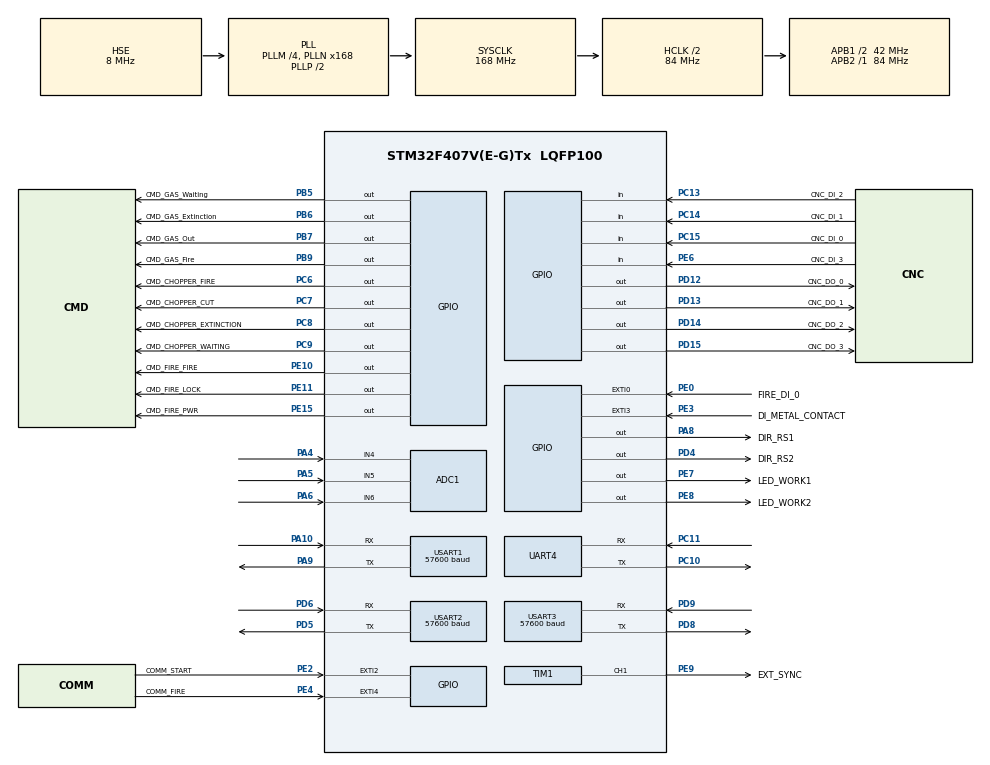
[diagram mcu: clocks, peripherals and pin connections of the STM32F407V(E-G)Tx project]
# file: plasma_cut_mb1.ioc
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ADC1.Channel-0\#ChannelRegularConversion=ADC_CHANNEL_4
ADC1.Channel-1\#ChannelRegularConversion=ADC_CHANNEL_5
ADC1.Channel-2\#ChannelRegularConversion=ADC_CHANNEL_6
ADC1.ContinuousConvMode=ENABLE
ADC1.DMAContinuousRequests=ENABLE
ADC1.DiscontinuousConvMode=DISABLE
ADC1.EOCSelection=ADC_EOC_SEQ_CONV
ADC1.InjNumberOfConversion=0
ADC1.NbrOfConversion=3
ADC1.NbrOfConversionFlag=1
ADC1.Rank-0\#ChannelRegularConversion=1
ADC1.Rank-1\#ChannelRegularConversion=2
ADC1.Rank-2\#ChannelRegularConversion=3
ADC1.SamplingTime-0\#ChannelRegularConversion=ADC_SAMPLETIME_112CYCLES
ADC1.SamplingTime-1\#ChannelRegularConversion=ADC_SAMPLETIME_112CYCLES
ADC1.SamplingTime-2\#ChannelRegularConversion=ADC_SAMPLETIME_112CYCLES
ADC1.master=1
Dma.ADC1.4.Direction=DMA_PERIPH_TO_MEMORY
Dma.ADC1.4.FIFOMode=DMA_FIFOMODE_DISABLE
Dma.ADC1.4.Instance=DMA2_Stream0
Dma.ADC1.4.MemDataAlignment=DMA_MDATAALIGN_HALFWORD
Dma.ADC1.4.MemInc=DMA_MINC_ENABLE
Dma.ADC1.4.Mode=DMA_CIRCULAR
Dma.ADC1.4.PeriphDataAlignment=DMA_PDATAALIGN_HALFWORD
Dma.ADC1.4.PeriphInc=DMA_PINC_DISABLE
Dma.ADC1.4.Priority=DMA_PRIORITY_LOW
Dma.Request0=USART1_TX
Dma.Request1=USART2_TX
Dma.Request2=USART3_TX
Dma.Request3=UART4_TX
Dma.Request4=ADC1
Dma.UART4_TX.3.Direction=DMA_MEMORY_TO_PERIPH
Dma.UART4_TX.3.FIFOMode=DMA_FIFOMODE_DISABLE
Dma.UART4_TX.3.Instance=DMA1_Stream4
Dma.UART4_TX.3.MemDataAlignment=DMA_MDATAALIGN_BYTE
Dma.UART4_TX.3.MemInc=DMA_MINC_ENABLE
Dma.UART4_TX.3.Mode=DMA_NORMAL
Dma.UART4_TX.3.PeriphDataAlignment=DMA_PDATAALIGN_BYTE
Dma.UART4_TX.3.PeriphInc=DMA_PINC_DISABLE
Dma.UART4_TX.3.Priority=DMA_PRIORITY_LOW
Dma.USART1_TX.0.Direction=DMA_MEMORY_TO_PERIPH
Dma.USART1_TX.0.FIFOMode=DMA_FIFOMODE_DISABLE
Dma.USART1_TX.0.Instance=DMA2_Stream7
Dma.USART1_TX.0.MemDataAlignment=DMA_MDATAALIGN_BYTE
Dma.USART1_TX.0.MemInc=DMA_MINC_ENABLE
Dma.USART1_TX.0.Mode=DMA_NORMAL
Dma.USART1_TX.0.PeriphDataAlignment=DMA_PDATAALIGN_BYTE
Dma.USART1_TX.0.PeriphInc=DMA_PINC_DISABLE
Dma.USART1_TX.0.Priority=DMA_PRIORITY_LOW
Dma.USART2_TX.1.Direction=DMA_MEMORY_TO_PERIPH
Dma.USART2_TX.1.FIFOMode=DMA_FIFOMODE_DISABLE
Dma.USART2_TX.1.Instance=DMA1_Stream6
Dma.USART2_TX.1.MemDataAlignment=DMA_MDATAALIGN_BYTE
Dma.USART2_TX.1.MemInc=DMA_MINC_ENABLE
Dma.USART2_TX.1.Mode=DMA_NORMAL
Dma.USART2_TX.1.PeriphDataAlignment=DMA_PDATAALIGN_BYTE
Dma.USART2_TX.1.PeriphInc=DMA_PINC_DISABLE
Dma.USART2_TX.1.Priority=DMA_PRIORITY_LOW
Dma.USART3_TX.2.Direction=DMA_MEMORY_TO_PERIPH
Dma.USART3_TX.2.FIFOMode=DMA_FIFOMODE_DISABLE
Dma.USART3_TX.2.Instance=DMA1_Stream3
Dma.USART3_TX.2.MemDataAlignment=DMA_MDATAALIGN_BYTE
Dma.USART3_TX.2.MemInc=DMA_MINC_ENABLE
Dma.USART3_TX.2.Mode=DMA_NORMAL
Dma.USART3_TX.2.PeriphDataAlignment=DMA_PDATAALIGN_BYTE
Dma.USART3_TX.2.PeriphInc=DMA_PINC_DISABLE
Dma.USART3_TX.2.Priority=DMA_PRIORITY_LOW
Mcu.Family=STM32F4
Mcu.Name=STM32F407V(E-G)Tx
Mcu.Package=LQFP100
NVIC.DMA1_Stream3_IRQn=true\:0\:0\:false\:false\:true\:false\:true\:true
NVIC.DMA1_Stream4_IRQn=true\:0\:0\:false\:false\:true\:false\:true\:true
NVIC.DMA1_Stream6_IRQn=true\:0\:0\:false\:false\:true\:false\:true\:true
NVIC.DMA2_Stream0_IRQn=true\:0\:0\:false\:false\:true\:false\:true\:true
NVIC.DMA2_Stream7_IRQn=true\:0\:0\:false\:false\:true\:false\:true\:true
NVIC.EXTI0_IRQn=true\:0\:0\:false\:false\:true\:true\:true\:true
NVIC.EXTI2_IRQn=true\:0\:0\:false\:false\:true\:true\:true\:true
NVIC.EXTI3_IRQn=true\:0\:0\:false\:false\:true\:true\:true\:true
NVIC.EXTI4_IRQn=true\:0\:0\:false\:false\:true\:true\:true\:true
NVIC.PriorityGroup=NVIC_PRIORITYGROUP_4
NVIC.TIM3_IRQn=true\:0\:0\:false\:false\:true\:true\:true\:true
NVIC.TIM4_IRQn=true\:0\:0\:false\:false\:true\:true\:true\:true
NVIC.UART4_IRQn=true\:0\:0\:false\:false\:true\:true\:true\:true
NVIC.USART1_IRQn=true\:0\:0\:false\:false\:true\:true\:true\:true
NVIC.USART2_IRQn=true\:0\:0\:false\:false\:true\:true\:true\:true
NVIC.USART3_IRQn=true\:0\:0\:false\:false\:true\:true\:true\:true
PA10.Mode=Asynchronous
PA10.Signal=USART1_RX
PA13.Mode=Serial_Wire
PA13.Signal=SYS_JTMS-SWDIO
PA14.Mode=Serial_Wire
PA14.Signal=SYS_JTCK-SWCLK
PA4.Signal=ADCx_IN4
PA5.Signal=ADCx_IN5
PA6.Signal=ADCx_IN6
PA8.GPIO_Label=DIR_RS1
PA8.Signal=GPIO_Output
PA9.Mode=Asynchronous
PA9.Signal=USART1_TX
PB5.GPIO_Label=CMD_GAS_Waiting
PB5.GPIO_ModeDefaultOutputPP=GPIO_MODE_OUTPUT_PP
PB5.GPIO_PuPd=GPIO_PULLDOWN
PB5.GPIO_Speed=GPIO_SPEED_FREQ_MEDIUM
PB5.PinState=GPIO_PIN_RESET
PB5.Signal=GPIO_Output
PB6.GPIO_Label=CMD_GAS_Extinction
PB6.GPIO_ModeDefaultOutputPP=GPIO_MODE_OUTPUT_PP
PB6.GPIO_PuPd=GPIO_PULLDOWN
PB6.GPIO_Speed=GPIO_SPEED_FREQ_MEDIUM
PB6.PinState=GPIO_PIN_RESET
PB6.Signal=GPIO_Output
PB7.GPIO_Label=CMD_GAS_Out
PB7.GPIO_ModeDefaultOutputPP=GPIO_MODE_OUTPUT_PP
PB7.GPIO_PuPd=GPIO_PULLDOWN
PB7.GPIO_Speed=GPIO_SPEED_FREQ_MEDIUM
PB7.PinState=GPIO_PIN_RESET
PB7.Signal=GPIO_Output
PB8.Signal=S_TIM10_CH1
PB9.GPIO_Label=CMD_GAS_Fire
PB9.GPIO_ModeDefaultOutputPP=GPIO_MODE_OUTPUT_PP
PB9.GPIO_PuPd=GPIO_PULLDOWN
PB9.GPIO_Speed=GPIO_SPEED_FREQ_MEDIUM
PB9.PinState=GPIO_PIN_RESET
PB9.Signal=GPIO_Output
PC10.Mode=Asynchronous
PC10.Signal=UART4_TX
PC11.Mode=Asynchronous
PC11.Signal=UART4_RX
PC13-ANTI_TAMP.GPIO_Label=CNC_DI_2
PC13-ANTI_TAMP.Signal=GPIO_Input
PC14-OSC32_IN.GPIO_Label=CNC_DI_1
PC14-OSC32_IN.Signal=GPIO_Input
PC15-OSC32_OUT.GPIO_Label=CNC_DI_0
PC15-OSC32_OUT.Signal=GPIO_Input
PC6.GPIO_Label=CMD_CHOPPER_FIRE
PC6.Signal=GPIO_Output
PC7.GPIO_Label=CMD_CHOPPER_CUT
PC7.Signal=GPIO_Output
PC8.GPIO_Label=CMD_CHOPPER_EXTINCTION
PC8.Signal=GPIO_Output
PC9.GPIO_Label=CMD_CHOPPER_WAITING
PC9.Signal=GPIO_Output
PD0.Signal=CAN1_RX
PD12.GPIO_Label=CNC_DO_0
PD12.GPIO_ModeDefaultOutputPP=GPIO_MODE_OUTPUT_PP
PD12.GPIO_PuPd=GPIO_PULLDOWN
PD12.GPIO_Speed=GPIO_SPEED_FREQ_LOW
PD12.PinState=GPIO_PIN_RESET
PD12.Signal=GPIO_Output
PD13.GPIO_Label=CNC_DO_1
PD13.GPIO_ModeDefaultOutputPP=GPIO_MODE_OUTPUT_PP
PD13.GPIO_PuPd=GPIO_PULLDOWN
PD13.GPIO_Speed=GPIO_SPEED_FREQ_LOW
PD13.PinState=GPIO_PIN_RESET
PD13.Signal=GPIO_Output
PD14.GPIO_Label=CNC_DO_2
PD14.GPIO_ModeDefaultOutputPP=GPIO_MODE_OUTPUT_PP
PD14.GPIO_PuPd=GPIO_PULLDOWN
PD14.GPIO_Speed=GPIO_SPEED_FREQ_LOW
PD14.PinState=GPIO_PIN_RESET
PD14.Signal=GPIO_Output
PD15.GPIO_Label=CNC_DO_3
PD15.GPIO_ModeDefaultOutputPP=GPIO_MODE_OUTPUT_PP
PD15.GPIO_PuPd=GPIO_PULLDOWN
PD15.GPIO_Speed=GPIO_SPEED_FREQ_LOW
PD15.PinState=GPIO_PIN_RESET
PD15.Signal=GPIO_Output
PD4.GPIO_Label=DIR_RS2
PD4.Signal=GPIO_Output
PD5.Mode=Asynchronous
PD5.Signal=USART2_TX
PD6.Mode=Asynchronous
PD6.Signal=USART2_RX
PD8.Mode=Asynchronous
PD8.Signal=USART3_TX
PD9.Mode=Asynchronous
PD9.Signal=USART3_RX
PE0.GPIO_Label=FIRE_DI_0
PE0.Signal=GPXTI0
PE10.GPIO_Label=CMD_FIRE_FIRE
PE10.Signal=GPIO_Output
PE11.GPIO_Label=CMD_FIRE_LOCK
PE11.Signal=GPIO_Output
PE15.GPIO_Label=CMD_FIRE_PWR
PE15.Signal=GPIO_Output
PE2.GPIO_Label=COMM_START
PE2.GPIO_ModeDefaultEXTI=GPIO_MODE_IT_FALLING
PE2.Signal=GPXTI2
PE3.GPIO_Label=DI_METAL_CONTACT
PE3.GPIO_ModeDefaultEXTI=GPIO_MODE_IT_FALLING
PE3.Signal=GPXTI3
PE4.GPIO_Label=COMM_FIRE
PE4.GPIO_ModeDefaultEXTI=GPIO_MODE_IT_FALLING
PE4.Signal=GPXTI4
PE6.GPIO_Label=CNC_DI_3
PE6.Signal=GPIO_Input
PE7.GPIO_Label=LED_WORK1
PE7.Signal=GPIO_Output
PE8.GPIO_Label=LED_WORK2
PE8.Signal=GPIO_Output
PE9.GPIO_Label=EXT_SYNC
PE9.Signal=S_TIM1_CH1
PH0-OSC_IN.Mode=HSE-External-Oscillator
PH0-OSC_IN.Signal=RCC_OSC_IN
PH1-OSC_OUT.Mode=HSE-External-Oscillator
PH1-OSC_OUT.Signal=RCC_OSC_OUT
ProjectManager.HeapSize=0x1200
ProjectManager.StackSize=0x2000
ProjectManager.TargetToolchain=EWARM V8.32
RCC.48MHZClocksFreq_Value=84000000
RCC.AHBCLKDivider=RCC_SYSCLK_DIV2
RCC.AHBFreq_Value=84000000
RCC.APB1CLKDivider=RCC_HCLK_DIV2
RCC.APB1Freq_Value=42000000
RCC.APB1TimFreq_Value=84000000
RCC.APB2Freq_Value=84000000
RCC.APB2TimFreq_Value=84000000
RCC.CortexFreq_Value=84000000
RCC.HCLKFreq_Value=84000000
RCC.HSE_VALUE=8000000
RCC.HSI_VALUE=16000000
RCC.LSE_VALUE=32768
RCC.PLLM=4
RCC.PLLN=168
RCC.PLLSourceVirtual=RCC_PLLSOURCE_HSE
RCC.SYSCLKFreq_VALUE=168000000
RCC.SYSCLKSource=RCC_SYSCLKSOURCE_PLLCLK
RCC.VCOOutputFreq_Value=336000000
SH.ADCx_IN4.0=ADC1_IN4,IN4
SH.ADCx_IN5.0=ADC1_IN5,IN5
SH.ADCx_IN6.0=ADC1_IN6,IN6
SH.S_TIM10_CH1.0=TIM10_CH1
SH.S_TIM1_CH1.0=TIM1_CH1,PWM Generation1 CH1
TIM1.AutoReloadPreload=TIM_AUTORELOAD_PRELOAD_ENABLE
TIM1.Channel-PWM\ Generation1\ CH1=TIM_CHANNEL_1
TIM1.Period=7000
TIM1.Pulse-PWM\ Generation1\ CH1=3500
TIM3.AutoReloadPreload=TIM_AUTORELOAD_PRELOAD_ENABLE
TIM3.TIM_MasterOutputTrigger=TIM_TRGO_UPDATE
TIM4.AutoReloadPreload=TIM_AUTORELOAD_PRELOAD_ENABLE
TIM4.TIM_MasterOutputTrigger=TIM_TRGO_UPDATE
UART4.VirtualMode=Asynchronous
USART1.BaudRate=57600
USART1.VirtualMode=VM_ASYNC
USART2.BaudRate=57600
USART2.VirtualMode=VM_ASYNC
USART3.BaudRate=57600
USART3.VirtualMode=VM_ASYNC
VP_TIM1_VS_ClockSourceINT.Mode=Internal
VP_TIM3_VS_ClockSourceINT.Mode=Internal
VP_TIM4_VS_ClockSourceINT.Mode=Internal
board=custom

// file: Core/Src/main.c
/* USER CODE BEGIN Header */
/**
  ******************************************************************************
  * @file           : main.c
  * @brief          : Main program body
  ******************************************************************************
  * @attention
  *
  * Copyright (c) 2023 STMicroelectronics.
  * All rights reserved.
  *
  * This software is licensed under terms that can be found in the LICENSE file
  * in the root directory of this software component.
  * If no LICENSE file comes with this software, it is provided AS-IS.
  *
  ******************************************************************************
  */
/* USER CODE END Header */
#include "main.h"

/* USER CODE BEGIN Includes */
#include "StateMachine.h"
/* USER CODE END Includes */

ADC_HandleTypeDef hadc1;
DMA_HandleTypeDef hdma_adc1;

TIM_HandleTypeDef htim1;
TIM_HandleTypeDef htim3;
TIM_HandleTypeDef htim4;

UART_HandleTypeDef huart4;
UART_HandleTypeDef huart1;
UART_HandleTypeDef huart2;
UART_HandleTypeDef huart3;
DMA_HandleTypeDef hdma_uart4_tx;
DMA_HandleTypeDef hdma_usart1_tx;
DMA_HandleTypeDef hdma_usart2_tx;
DMA_HandleTypeDef hdma_usart3_tx;

/* USER CODE BEGIN PV */

UART_HandleTypeDef* pMBSlave     = &huart1; // RS485_1_slave(to PC)
UART_HandleTypeDef* pMBMaster    = &huart2; // RS485_2_master(to Cells)

UART_HandleTypeDef* pUartWIFI    = &huart4; // WIFI
UART_HandleTypeDef* pUartDBG     = &huart3; // UART_DEBUG

TIM_HandleTypeDef* pMBTimMaster = &htim3; //
TIM_HandleTypeDef* pMBTimSlave  = &htim4; //
TIM_HandleTypeDef* pExtSync     = &htim1; //

/* USER CODE END PV */

void SystemClock_Config(void);
static void MX_GPIO_Init(void);
static void MX_DMA_Init(void);
static void MX_USART3_UART_Init(void);
static void MX_UART4_Init(void);
static void MX_USART1_UART_Init(void);
static void MX_USART2_UART_Init(void);
static void MX_ADC1_Init(void);
static void MX_TIM3_Init(void);
static void MX_TIM4_Init(void);
static void MX_TIM1_Init(void);

int main(void)
{

  /* MCU Configuration--------------------------------------------------------*/

  /* Reset of all peripherals, Initializes the Flash interface and the Systick. */
  HAL_Init();

  /* Configure the system clock */
  SystemClock_Config();

  /* Initialize all configured peripherals */
  MX_GPIO_Init();
  MX_DMA_Init();
  MX_USART3_UART_Init();
  MX_UART4_Init();
  MX_USART1_UART_Init();
  MX_USART2_UART_Init();
  MX_ADC1_Init();
  MX_TIM3_Init();
  MX_TIM4_Init();
  MX_TIM1_Init();
  /* USER CODE BEGIN 2 */
  ProcessInit();
  if ( HAL_OK != HAL_ADC_Start_DMA( &hadc1, (uint32_t*)ADCdata,  eChanMax*ADC_BUF_LENGHT ))
  {
    Error_Handler();
  }
  /* USER CODE END 2 */

  /* Infinite loop */
  /* USER CODE BEGIN WHILE */
  while ( 1 )
  {
    SM_loop( );
    /* USER CODE END WHILE */

  }
}

void SystemClock_Config(void)
{
  RCC_OscInitTypeDef RCC_OscInitStruct = {0};
  RCC_ClkInitTypeDef RCC_ClkInitStruct = {0};

  /** Configure the main internal regulator output voltage
  */
  __HAL_RCC_PWR_CLK_ENABLE();
  __HAL_PWR_VOLTAGESCALING_CONFIG(PWR_REGULATOR_VOLTAGE_SCALE1);

  /** Initializes the RCC Oscillators according to the specified parameters
  * in the RCC_OscInitTypeDef structure.
  */
  RCC_OscInitStruct.OscillatorType = RCC_OSCILLATORTYPE_HSE;
  RCC_OscInitStruct.HSEState = RCC_HSE_ON;
  RCC_OscInitStruct.PLL.PLLState = RCC_PLL_ON;
  RCC_OscInitStruct.PLL.PLLSource = RCC_PLLSOURCE_HSE;
  RCC_OscInitStruct.PLL.PLLM = 4;
  RCC_OscInitStruct.PLL.PLLN = 168;
  RCC_OscInitStruct.PLL.PLLP = RCC_PLLP_DIV2;
  RCC_OscInitStruct.PLL.PLLQ = 4;
  if (HAL_RCC_OscConfig(&RCC_OscInitStruct) != HAL_OK)
  {
    Error_Handler();
  }

  /** Initializes the CPU, AHB and APB buses clocks
  */
  RCC_ClkInitStruct.ClockType = RCC_CLOCKTYPE_HCLK|RCC_CLOCKTYPE_SYSCLK
                              |RCC_CLOCKTYPE_PCLK1|RCC_CLOCKTYPE_PCLK2;
  RCC_ClkInitStruct.SYSCLKSource = RCC_SYSCLKSOURCE_PLLCLK;
  RCC_ClkInitStruct.AHBCLKDivider = RCC_SYSCLK_DIV2;
  RCC_ClkInitStruct.APB1CLKDivider = RCC_HCLK_DIV2;
  RCC_ClkInitStruct.APB2CLKDivider = RCC_HCLK_DIV1;

  if (HAL_RCC_ClockConfig(&RCC_ClkInitStruct, FLASH_LATENCY_2) != HAL_OK)
  {
    Error_Handler();
  }
}

static void MX_ADC1_Init(void)
{

  ADC_ChannelConfTypeDef sConfig = {0};

  /** Configure the global features of the ADC (Clock, Resolution, Data Alignment and number of conversion)
  */
  hadc1.Instance = ADC1;
  hadc1.Init.ClockPrescaler = ADC_CLOCK_SYNC_PCLK_DIV4;
  hadc1.Init.Resolution = ADC_RESOLUTION_12B;
  hadc1.Init.ScanConvMode = ENABLE;
  hadc1.Init.ContinuousConvMode = ENABLE;
  hadc1.Init.DiscontinuousConvMode = DISABLE;
  hadc1.Init.ExternalTrigConvEdge = ADC_EXTERNALTRIGCONVEDGE_NONE;
  hadc1.Init.ExternalTrigConv = ADC_SOFTWARE_START;
  hadc1.Init.DataAlign = ADC_DATAALIGN_RIGHT;
  hadc1.Init.NbrOfConversion = 3;
  hadc1.Init.DMAContinuousRequests = ENABLE;
  hadc1.Init.EOCSelection = ADC_EOC_SEQ_CONV;
  if (HAL_ADC_Init(&hadc1) != HAL_OK)
  {
    Error_Handler();
  }

  /** Configure for the selected ADC regular channel its corresponding rank in the sequencer and its sample time.
  */
  sConfig.Channel = ADC_CHANNEL_4;
  sConfig.Rank = 1;
  sConfig.SamplingTime = ADC_SAMPLETIME_112CYCLES;
  if (HAL_ADC_ConfigChannel(&hadc1, &sConfig) != HAL_OK)
  {
    Error_Handler();
  }

  /** Configure for the selected ADC regular channel its corresponding rank in the sequencer and its sample time.
  */
  sConfig.Channel = ADC_CHANNEL_5;
  sConfig.Rank = 2;
  if (HAL_ADC_ConfigChannel(&hadc1, &sConfig) != HAL_OK)
  {
    Error_Handler();
  }

  /** Configure for the selected ADC regular channel its corresponding rank in the sequencer and its sample time.
  */
  sConfig.Channel = ADC_CHANNEL_6;
  sConfig.Rank = 3;
  if (HAL_ADC_ConfigChannel(&hadc1, &sConfig) != HAL_OK)
  {
    Error_Handler();
  }
  /* USER CODE BEGIN ADC1_Init 2 */
  sConfig.Channel = ADC_CHANNEL_4;
  /* USER CODE END ADC1_Init 2 */

}

static void MX_TIM1_Init(void)
{

  TIM_ClockConfigTypeDef sClockSourceConfig = {0};
  TIM_MasterConfigTypeDef sMasterConfig = {0};
  TIM_OC_InitTypeDef sConfigOC = {0};
  TIM_BreakDeadTimeConfigTypeDef sBreakDeadTimeConfig = {0};

  htim1.Instance = TIM1;
  htim1.Init.Prescaler = 0;
  htim1.Init.CounterMode = TIM_COUNTERMODE_UP;
  htim1.Init.Period = 7000;
  htim1.Init.ClockDivision = TIM_CLOCKDIVISION_DIV1;
  htim1.Init.RepetitionCounter = 0;
  htim1.Init.AutoReloadPreload = TIM_AUTORELOAD_PRELOAD_ENABLE;
  if (HAL_TIM_Base_Init(&htim1) != HAL_OK)
  {
    Error_Handler();
  }
  sClockSourceConfig.ClockSource = TIM_CLOCKSOURCE_INTERNAL;
  if (HAL_TIM_ConfigClockSource(&htim1, &sClockSourceConfig) != HAL_OK)
  {
    Error_Handler();
  }
  if (HAL_TIM_PWM_Init(&htim1) != HAL_OK)
  {
    Error_Handler();
  }
  sMasterConfig.MasterOutputTrigger = TIM_TRGO_RESET;
  sMasterConfig.MasterSlaveMode = TIM_MASTERSLAVEMODE_DISABLE;
  if (HAL_TIMEx_MasterConfigSynchronization(&htim1, &sMasterConfig) != HAL_OK)
  {
    Error_Handler();
  }
  sConfigOC.OCMode = TIM_OCMODE_PWM1;
  sConfigOC.Pulse = 3500;
  sConfigOC.OCPolarity = TIM_OCPOLARITY_HIGH;
  sConfigOC.OCNPolarity = TIM_OCNPOLARITY_HIGH;
  sConfigOC.OCFastMode = TIM_OCFAST_DISABLE;
  sConfigOC.OCIdleState = TIM_OCIDLESTATE_RESET;
  sConfigOC.OCNIdleState = TIM_OCNIDLESTATE_RESET;
  if (HAL_TIM_PWM_ConfigChannel(&htim1, &sConfigOC, TIM_CHANNEL_1) != HAL_OK)
  {
    Error_Handler();
  }
  sBreakDeadTimeConfig.OffStateRunMode = TIM_OSSR_DISABLE;
  sBreakDeadTimeConfig.OffStateIDLEMode = TIM_OSSI_DISABLE;
  sBreakDeadTimeConfig.LockLevel = TIM_LOCKLEVEL_OFF;
  sBreakDeadTimeConfig.DeadTime = 0;
  sBreakDeadTimeConfig.BreakState = TIM_BREAK_DISABLE;
  sBreakDeadTimeConfig.BreakPolarity = TIM_BREAKPOLARITY_HIGH;
  sBreakDeadTimeConfig.AutomaticOutput = TIM_AUTOMATICOUTPUT_DISABLE;
  if (HAL_TIMEx_ConfigBreakDeadTime(&htim1, &sBreakDeadTimeConfig) != HAL_OK)
  {
    Error_Handler();
  }
  HAL_TIM_MspPostInit(&htim1);

}

static void MX_TIM3_Init(void)
{

  TIM_ClockConfigTypeDef sClockSourceConfig = {0};
  TIM_MasterConfigTypeDef sMasterConfig = {0};

  htim3.Instance = TIM3;
  htim3.Init.Prescaler = 0;
  htim3.Init.CounterMode = TIM_COUNTERMODE_UP;
  htim3.Init.Period = 65535;
  htim3.Init.ClockDivision = TIM_CLOCKDIVISION_DIV1;
  htim3.Init.AutoReloadPreload = TIM_AUTORELOAD_PRELOAD_ENABLE;
  if (HAL_TIM_Base_Init(&htim3) != HAL_OK)
  {
    Error_Handler();
  }
  sClockSourceConfig.ClockSource = TIM_CLOCKSOURCE_INTERNAL;
  if (HAL_TIM_ConfigClockSource(&htim3, &sClockSourceConfig) != HAL_OK)
  {
    Error_Handler();
  }
  sMasterConfig.MasterOutputTrigger = TIM_TRGO_UPDATE;
  sMasterConfig.MasterSlaveMode = TIM_MASTERSLAVEMODE_DISABLE;
  if (HAL_TIMEx_MasterConfigSynchronization(&htim3, &sMasterConfig) != HAL_OK)
  {
    Error_Handler();
  }

}

static void MX_TIM4_Init(void)
{

  TIM_ClockConfigTypeDef sClockSourceConfig = {0};
  TIM_MasterConfigTypeDef sMasterConfig = {0};

  htim4.Instance = TIM4;
  htim4.Init.Prescaler = 0;
  htim4.Init.CounterMode = TIM_COUNTERMODE_UP;
  htim4.Init.Period = 65535;
  htim4.Init.ClockDivision = TIM_CLOCKDIVISION_DIV1;
  htim4.Init.AutoReloadPreload = TIM_AUTORELOAD_PRELOAD_ENABLE;
  if (HAL_TIM_Base_Init(&htim4) != HAL_OK)
  {
    Error_Handler();
  }
  sClockSourceConfig.ClockSource = TIM_CLOCKSOURCE_INTERNAL;
  if (HAL_TIM_ConfigClockSource(&htim4, &sClockSourceConfig) != HAL_OK)
  {
    Error_Handler();
  }
  sMasterConfig.MasterOutputTrigger = TIM_TRGO_UPDATE;
  sMasterConfig.MasterSlaveMode = TIM_MASTERSLAVEMODE_DISABLE;
  if (HAL_TIMEx_MasterConfigSynchronization(&htim4, &sMasterConfig) != HAL_OK)
  {
    Error_Handler();
  }

}

static void MX_UART4_Init(void)
{

  huart4.Instance = UART4;
  huart4.Init.BaudRate = 115200;
  huart4.Init.WordLength = UART_WORDLENGTH_8B;
  huart4.Init.StopBits = UART_STOPBITS_1;
  huart4.Init.Parity = UART_PARITY_NONE;
  huart4.Init.Mode = UART_MODE_TX_RX;
  huart4.Init.HwFlowCtl = UART_HWCONTROL_NONE;
  huart4.Init.OverSampling = UART_OVERSAMPLING_16;
  if (HAL_UART_Init(&huart4) != HAL_OK)
  {
    Error_Handler();
  }

}

static void MX_USART1_UART_Init(void)
{

  huart1.Instance = USART1;
  huart1.Init.BaudRate = 57600;
  huart1.Init.WordLength = UART_WORDLENGTH_8B;
  huart1.Init.StopBits = UART_STOPBITS_1;
  huart1.Init.Parity = UART_PARITY_NONE;
  huart1.Init.Mode = UART_MODE_TX_RX;
  huart1.Init.HwFlowCtl = UART_HWCONTROL_NONE;
  huart1.Init.OverSampling = UART_OVERSAMPLING_16;
  if (HAL_UART_Init(&huart1) != HAL_OK)
  {
    Error_Handler();
  }

}

static void MX_USART2_UART_Init(void)
{

  huart2.Instance = USART2;
  huart2.Init.BaudRate = 57600;
  huart2.Init.WordLength = UART_WORDLENGTH_8B;
  huart2.Init.StopBits = UART_STOPBITS_1;
  huart2.Init.Parity = UART_PARITY_NONE;
  huart2.Init.Mode = UART_MODE_TX_RX;
  huart2.Init.HwFlowCtl = UART_HWCONTROL_NONE;
  huart2.Init.OverSampling = UART_OVERSAMPLING_16;
  if (HAL_UART_Init(&huart2) != HAL_OK)
  {
    Error_Handler();
  }

}

static void MX_USART3_UART_Init(void)
{

  huart3.Instance = USART3;
  huart3.Init.BaudRate = 57600;
  huart3.Init.WordLength = UART_WORDLENGTH_8B;
  huart3.Init.StopBits = UART_STOPBITS_1;
  huart3.Init.Parity = UART_PARITY_NONE;
  huart3.Init.Mode = UART_MODE_TX_RX;
  huart3.Init.HwFlowCtl = UART_HWCONTROL_NONE;
  huart3.Init.OverSampling = UART_OVERSAMPLING_16;
  if (HAL_UART_Init(&huart3) != HAL_OK)
  {
    Error_Handler();
  }

}

static void MX_DMA_Init(void)
{

  /* DMA controller clock enable */
  __HAL_RCC_DMA2_CLK_ENABLE();
  __HAL_RCC_DMA1_CLK_ENABLE();

  /* DMA interrupt init */
  /* DMA1_Stream3_IRQn interrupt configuration */
  HAL_NVIC_SetPriority(DMA1_Stream3_IRQn, 0, 0);
  HAL_NVIC_EnableIRQ(DMA1_Stream3_IRQn);
  /* DMA1_Stream4_IRQn interrupt configuration */
  HAL_NVIC_SetPriority(DMA1_Stream4_IRQn, 0, 0);
  HAL_NVIC_EnableIRQ(DMA1_Stream4_IRQn);
  /* DMA1_Stream6_IRQn interrupt configuration */
  HAL_NVIC_SetPriority(DMA1_Stream6_IRQn, 0, 0);
  HAL_NVIC_EnableIRQ(DMA1_Stream6_IRQn);
  /* DMA2_Stream0_IRQn interrupt configuration */
  HAL_NVIC_SetPriority(DMA2_Stream0_IRQn, 0, 0);
  HAL_NVIC_EnableIRQ(DMA2_Stream0_IRQn);
  /* DMA2_Stream7_IRQn interrupt configuration */
  HAL_NVIC_SetPriority(DMA2_Stream7_IRQn, 0, 0);
  HAL_NVIC_EnableIRQ(DMA2_Stream7_IRQn);

}

static void MX_GPIO_Init(void)
{
  GPIO_InitTypeDef GPIO_InitStruct = {0};

  /* GPIO Ports Clock Enable */
  __HAL_RCC_GPIOE_CLK_ENABLE();
  __HAL_RCC_GPIOC_CLK_ENABLE();
  __HAL_RCC_GPIOH_CLK_ENABLE();
  __HAL_RCC_GPIOA_CLK_ENABLE();
  __HAL_RCC_GPIOD_CLK_ENABLE();
  __HAL_RCC_GPIOB_CLK_ENABLE();

  /*Configure GPIO pin Output Level */
  HAL_GPIO_WritePin(GPIOE, LED_WORK1_Pin|LED_WORK2_Pin|CMD_FIRE_FIRE_Pin|CMD_FIRE_LOCK_Pin
                          |CMD_FIRE_PWR_Pin, GPIO_PIN_RESET);

  /*Configure GPIO pin Output Level */
  HAL_GPIO_WritePin(GPIOD, CNC_DO_0_Pin|CNC_DO_1_Pin|CNC_DO_2_Pin|CNC_DO_3_Pin
                          |DIR_RS2_Pin, GPIO_PIN_RESET);

  /*Configure GPIO pin Output Level */
  HAL_GPIO_WritePin(GPIOC, CMD_CHOPPER_FIRE_Pin|CMD_CHOPPER_CUT_Pin|CMD_CHOPPER_EXTINCTION_Pin|CMD_CHOPPER_WAITING_Pin, GPIO_PIN_RESET);

  /*Configure GPIO pin Output Level */
  HAL_GPIO_WritePin(DIR_RS1_GPIO_Port, DIR_RS1_Pin, GPIO_PIN_RESET);

  /*Configure GPIO pin Output Level */
  HAL_GPIO_WritePin(GPIOB, CMD_GAS_Waiting_Pin|CMD_GAS_Extinction_Pin|CMD_GAS_Out_Pin|CMD_GAS_Fire_Pin, GPIO_PIN_RESET);

  /*Configure GPIO pins : COMM_START_Pin DI_METAL_CONTACT_Pin COMM_FIRE_Pin */
  GPIO_InitStruct.Pin = COMM_START_Pin|DI_METAL_CONTACT_Pin|COMM_FIRE_Pin;
  GPIO_InitStruct.Mode = GPIO_MODE_IT_RISING_FALLING;//GPIO_MODE_IT_FALLING;
  GPIO_InitStruct.Pull = GPIO_NOPULL;
  HAL_GPIO_Init(GPIOE, &GPIO_InitStruct);

  /*Configure GPIO pin : CNC_DI_3_Pin */
  GPIO_InitStruct.Pin = CNC_DI_3_Pin;
  GPIO_InitStruct.Mode = GPIO_MODE_INPUT;
  GPIO_InitStruct.Pull = GPIO_NOPULL;
  HAL_GPIO_Init(CNC_DI_3_GPIO_Port, &GPIO_InitStruct);

  /*Configure GPIO pins : CNC_DI_2_Pin CNC_DI_1_Pin CNC_DI_0_Pin */
  GPIO_InitStruct.Pin = CNC_DI_2_Pin|CNC_DI_1_Pin|CNC_DI_0_Pin;
  GPIO_InitStruct.Mode = GPIO_MODE_INPUT;
  GPIO_InitStruct.Pull = GPIO_NOPULL;
  HAL_GPIO_Init(GPIOC, &GPIO_InitStruct);

  /*Configure GPIO pins : LED_WORK1_Pin LED_WORK2_Pin CMD_FIRE_FIRE_Pin CMD_FIRE_LOCK_Pin
                           CMD_FIRE_PWR_Pin */
  GPIO_InitStruct.Pin = LED_WORK1_Pin|LED_WORK2_Pin|CMD_FIRE_FIRE_Pin|CMD_FIRE_LOCK_Pin
                          |CMD_FIRE_PWR_Pin;
  GPIO_InitStruct.Mode = GPIO_MODE_OUTPUT_PP;
  GPIO_InitStruct.Pull = GPIO_NOPULL;
  GPIO_InitStruct.Speed = GPIO_SPEED_FREQ_LOW;
  HAL_GPIO_Init(GPIOE, &GPIO_InitStruct);

  /*Configure GPIO pins : CNC_DO_0_Pin CNC_DO_1_Pin CNC_DO_2_Pin CNC_DO_3_Pin */
  GPIO_InitStruct.Pin = CNC_DO_0_Pin|CNC_DO_1_Pin|CNC_DO_2_Pin|CNC_DO_3_Pin;
  GPIO_InitStruct.Mode = GPIO_MODE_OUTPUT_PP;
  GPIO_InitStruct.Pull = GPIO_PULLDOWN;
  GPIO_InitStruct.Speed = GPIO_SPEED_FREQ_LOW;
  HAL_GPIO_Init(GPIOD, &GPIO_InitStruct);

  /*Configure GPIO pins : CMD_CHOPPER_FIRE_Pin CMD_CHOPPER_CUT_Pin CMD_CHOPPER_EXTINCTION_Pin CMD_CHOPPER_WAITING_Pin */
  GPIO_InitStruct.Pin = CMD_CHOPPER_FIRE_Pin|CMD_CHOPPER_CUT_Pin|CMD_CHOPPER_EXTINCTION_Pin|CMD_CHOPPER_WAITING_Pin;
  GPIO_InitStruct.Mode = GPIO_MODE_OUTPUT_PP;
  GPIO_InitStruct.Pull = GPIO_NOPULL;
  GPIO_InitStruct.Speed = GPIO_SPEED_FREQ_LOW;
  HAL_GPIO_Init(GPIOC, &GPIO_InitStruct);

  /*Configure GPIO pin : DIR_RS1_Pin */
  GPIO_InitStruct.Pin = DIR_RS1_Pin;
  GPIO_InitStruct.Mode = GPIO_MODE_OUTPUT_PP;
  GPIO_InitStruct.Pull = GPIO_NOPULL;
  GPIO_InitStruct.Speed = GPIO_SPEED_FREQ_LOW;
  HAL_GPIO_Init(DIR_RS1_GPIO_Port, &GPIO_InitStruct);

  /*Configure GPIO pin : PD0 */
  GPIO_InitStruct.Pin = GPIO_PIN_0;
  GPIO_InitStruct.Mode = GPIO_MODE_AF_PP;
  GPIO_InitStruct.Pull = GPIO_NOPULL;
  GPIO_InitStruct.Speed = GPIO_SPEED_FREQ_VERY_HIGH;
  GPIO_InitStruct.Alternate = GPIO_AF9_CAN1;
  HAL_GPIO_Init(GPIOD, &GPIO_InitStruct);

  /*Configure GPIO pin : DIR_RS2_Pin */
  GPIO_InitStruct.Pin = DIR_RS2_Pin;
  GPIO_InitStruct.Mode = GPIO_MODE_OUTPUT_PP;
  GPIO_InitStruct.Pull = GPIO_NOPULL;
  GPIO_InitStruct.Speed = GPIO_SPEED_FREQ_LOW;
  HAL_GPIO_Init(DIR_RS2_GPIO_Port, &GPIO_InitStruct);

  /*Configure GPIO pins : CMD_GAS_Waiting_Pin CMD_GAS_Extinction_Pin CMD_GAS_Out_Pin CMD_GAS_Fire_Pin */
  GPIO_InitStruct.Pin = CMD_GAS_Waiting_Pin|CMD_GAS_Extinction_Pin|CMD_GAS_Out_Pin|CMD_GAS_Fire_Pin;
  GPIO_InitStruct.Mode = GPIO_MODE_OUTPUT_PP;
  GPIO_InitStruct.Pull = GPIO_PULLDOWN;
  GPIO_InitStruct.Speed = GPIO_SPEED_FREQ_MEDIUM;
  HAL_GPIO_Init(GPIOB, &GPIO_InitStruct);

  /*Configure GPIO pin : PB8 */
  GPIO_InitStruct.Pin = GPIO_PIN_8;
  GPIO_InitStruct.Mode = GPIO_MODE_AF_PP;
  GPIO_InitStruct.Pull = GPIO_NOPULL;
  GPIO_InitStruct.Speed = GPIO_SPEED_FREQ_LOW;
  GPIO_InitStruct.Alternate = GPIO_AF3_TIM10;
  HAL_GPIO_Init(GPIOB, &GPIO_InitStruct);

  /*Configure GPIO pin : FIRE_DI_0_Pin */
  GPIO_InitStruct.Pin = FIRE_DI_0_Pin;
  GPIO_InitStruct.Mode = GPIO_MODE_IT_RISING;
  GPIO_InitStruct.Pull = GPIO_NOPULL;
  HAL_GPIO_Init(FIRE_DI_0_GPIO_Port, &GPIO_InitStruct);

  /* EXTI interrupt init*/
  HAL_NVIC_SetPriority(EXTI0_IRQn, 0, 0);
  HAL_NVIC_EnableIRQ(EXTI0_IRQn);

  HAL_NVIC_SetPriority(EXTI2_IRQn, 0, 0);
  HAL_NVIC_EnableIRQ(EXTI2_IRQn);

  HAL_NVIC_SetPriority(EXTI3_IRQn, 0, 0);
  HAL_NVIC_EnableIRQ(EXTI3_IRQn);

  HAL_NVIC_SetPriority(EXTI4_IRQn, 0, 0);
  HAL_NVIC_EnableIRQ(EXTI4_IRQn);

}

void Error_Handler(void)
{
  __disable_irq();
  while (1)
  {
  }
}
